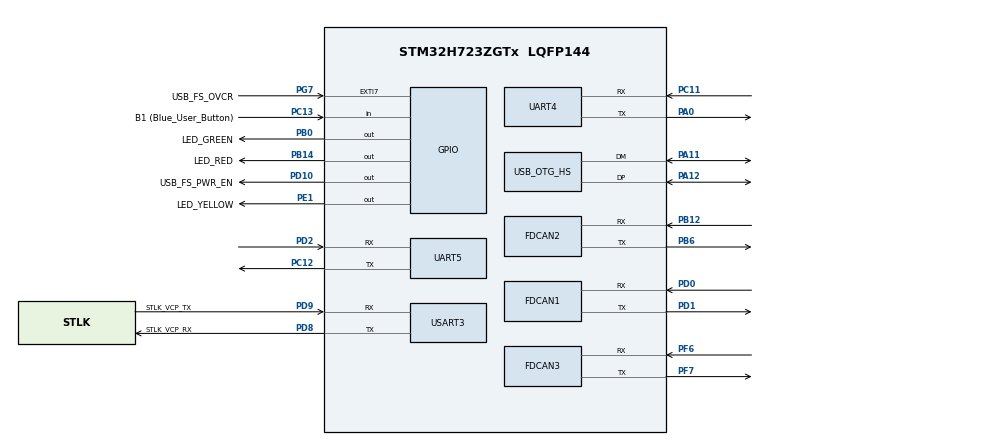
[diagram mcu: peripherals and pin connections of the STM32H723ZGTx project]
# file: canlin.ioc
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Mcu.Family=STM32H7
Mcu.Name=STM32H723ZGTx
Mcu.Package=LQFP144
NVIC.OTG_HS_IRQn=true\:0\:0\:false\:false\:true\:false\:true
NVIC.PriorityGroup=NVIC_PRIORITYGROUP_4
PA0.Mode=LIN
PA0.Signal=UART4_TX
PA1.GPIO_Label=RMII_REF_CLK
PA1.Signal=ETH_REF_CLK
PA10.GPIO_Label=USB_FS_ID
PA10.Signal=USB_OTG_HS_ID
PA11.Mode=Device_Only_FS
PA11.Signal=USB_OTG_HS_DM
PA12.Mode=Device_Only_FS
PA12.Signal=USB_OTG_HS_DP
PA13(JTMS/SWDIO).GPIO_Label=SWDIO
PA13(JTMS/SWDIO).Mode=Trace_Asynchronous_SW
PA13(JTMS/SWDIO).Signal=DEBUG_JTMS-SWDIO
PA14(JTCK/SWCLK).GPIO_Label=SWCLK
PA14(JTCK/SWCLK).Mode=Trace_Asynchronous_SW
PA14(JTCK/SWCLK).Signal=DEBUG_JTCK-SWCLK
PA2.GPIO_Label=RMII_MDIO
PA2.Signal=ETH_MDIO
PA7.GPIO_Label=RMII_CRS_DV
PA7.Signal=ETH_CRS_DV
PA9.GPIO_Label=USB_FS_VBUS
PA9.Signal=USB_OTG_HS_VBUS
PB0.GPIO_Label=LED_GREEN
PB0.Signal=GPIO_Output
PB12.Mode=FDCAN_Activate
PB12.Signal=FDCAN2_RX
PB13.GPIO_Label=RMII_TXD1
PB13.Signal=ETH_TXD1
PB14.GPIO_Label=LED_RED
PB14.Signal=GPIO_Output
PB3(JTDO/TRACESWO).GPIO_Label=SWO
PB3(JTDO/TRACESWO).Mode=Trace_Asynchronous_SW
PB3(JTDO/TRACESWO).Signal=DEBUG_JTDO-SWO
PB6.Mode=FDCAN_Activate
PB6.Signal=FDCAN2_TX
PC1.GPIO_Label=RMII_MDC
PC1.Signal=ETH_MDC
PC11.Mode=LIN
PC11.Signal=UART4_RX
PC12.Mode=LIN
PC12.Signal=UART5_TX
PC13.GPIO_Label=B1 (Blue_User_Button)
PC13.Signal=GPIO_Input
PC14-OSC32_IN.Mode=LSE-External-Oscillator
PC14-OSC32_IN.Signal=RCC_OSC32_IN
PC15-OSC32_OUT.Mode=LSE-External-Oscillator
PC15-OSC32_OUT.Signal=RCC_OSC32_OUT
PC4.GPIO_Label=RMII_RXD0
PC4.Signal=ETH_RXD0
PC5.GPIO_Label=RMII_RXD1
PC5.Signal=ETH_RXD1
PD0.Mode=FDCAN_Activate
PD0.Signal=FDCAN1_RX
PD1.Mode=FDCAN_Activate
PD1.Signal=FDCAN1_TX
PD10.GPIO_Label=USB_FS_PWR_EN
PD10.Signal=GPIO_Output
PD2.Mode=LIN
PD2.Signal=UART5_RX
PD8.GPIO_Label=STLK_VCP_RX
PD8.Mode=Asynchronous
PD8.Signal=USART3_TX
PD9.GPIO_Label=STLK_VCP_TX
PD9.Mode=Asynchronous
PD9.Signal=USART3_RX
PE1.GPIO_Label=LED_YELLOW
PE1.Signal=GPIO_Output
PF6.Mode=FDCAN_Activate
PF6.Signal=FDCAN3_RX
PF7.Mode=FDCAN_Activate
PF7.Signal=FDCAN3_TX
PG11.GPIO_Label=RMII_TX_EN
PG11.Signal=ETH_TX_EN
PG13.GPIO_Label=RMII_TXD0
PG13.Signal=ETH_TXD0
PG7.GPIO_Label=USB_FS_OVCR
PG7.Signal=GPXTI7
PH0-OSC_IN.GPIO_Label=MCO
PH0-OSC_IN.Mode=HSE-External-Clock-Source
PH0-OSC_IN.Signal=RCC_OSC_IN
PH1-OSC_OUT.Signal=RCC_OSC_OUT
ProjectManager.HeapSize=0x1000
ProjectManager.StackSize=0x1000
ProjectManager.TargetToolchain=STM32CubeIDE
RCC.ADCFreq_Value=76000000
RCC.APB1Freq_Value=70000000
RCC.APB2Freq_Value=70000000
RCC.APB3Freq_Value=70000000
RCC.APB4Freq_Value=70000000
RCC.CortexFreq_Value=280000000
RCC.D1PPRE=RCC_APB3_DIV2
RCC.D2PPRE1=RCC_APB1_DIV2
RCC.D2PPRE2=RCC_APB2_DIV2
RCC.D3PPRE=RCC_APB4_DIV2
RCC.DIVM1=4
RCC.DIVM2=1
RCC.DIVN1=140
RCC.DIVN2=19
RCC.DIVP1=1
RCC.DIVQ1=4
RCC.HCLKFreq_Value=140000000
RCC.HPRE=RCC_HCLK_DIV2
RCC.HSE_VALUE=8000000
RCC.PLL1_VCI_Range-AdvancedSettings=RCC_PLL1VCIRANGE_0
RCC.PLL1_VCO_SEL-AdvancedSettings=RCC_PLL1VCOMEDIUM
RCC.PLL2_VCI_Range-AdvancedSettings=RCC_PLL2VCIRANGE_0
RCC.PLL2_VCO_SEL-AdvancedSettings=RCC_PLL2VCOMEDIUM
RCC.PLL3_VCO_SEL-AdvancedSettings=RCC_PLL3VCOMEDIUM
RCC.PLLFRACN=0
RCC.PLLSourceVirtual=RCC_PLLSOURCE_HSE
RCC.SYSCLKFreq_VALUE=280000000
RCC.SYSCLKSource=RCC_SYSCLKSOURCE_PLLCLK
RCC.USBCLockSelection=RCC_USBCLKSOURCE_HSI48
RCC.USBFreq_Value=48000000
UART4.AutoBaudRateEnableParam=UART_ADVFEATURE_AUTOBAUDRATE_ENABLE
UART5.AutoBaudRateEnableParam=UART_ADVFEATURE_AUTOBAUDRATE_ENABLE
USART3.VirtualMode-Asynchronous=VM_ASYNC
USB_DEVICE.APP_RX_DATA_SIZE=512
USB_DEVICE.APP_TX_DATA_SIZE=4
USB_DEVICE.CLASS_NAME_HS=CDC
USB_DEVICE.VirtualMode=Cdc
USB_DEVICE.VirtualModeHS=Cdc_HS
USB_OTG_HS.VirtualMode-Device_Only_FS=Device_Only_FS
VP_USB_DEVICE_VS_USB_DEVICE_CDC_HS.Mode=CDC_HS
board=NUCLEO-H723ZG

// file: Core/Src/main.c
/* USER CODE BEGIN Header */
/**
  ******************************************************************************
  * @file           : main.c
  * @brief          : Main program body
  ******************************************************************************
  * @attention
  *
  * <h2><center>&copy; Copyright (c) 2021 STMicroelectronics.
  * All rights reserved.</center></h2>
  *
  * This software component is licensed by ST under BSD 3-Clause license,
  * the "License"; You may not use this file except in compliance with the
  * License. You may obtain a copy of the License at:
  *                        opensource.org/licenses/BSD-3-Clause
  *
  ******************************************************************************
  */
/* USER CODE END Header */
#include "main.h"
#include "usb_device.h"

/* USER CODE BEGIN Includes */
#include "console.h"

/* USER CODE END Includes */

FDCAN_HandleTypeDef hfdcan1;
FDCAN_HandleTypeDef hfdcan2;
FDCAN_HandleTypeDef hfdcan3;

UART_HandleTypeDef huart4;
UART_HandleTypeDef huart5;
UART_HandleTypeDef huart3;

void SystemClock_Config(void);
static void MX_GPIO_Init(void);
static void MX_USART3_UART_Init(void);
static void MX_FDCAN1_Init(void);
static void MX_FDCAN2_Init(void);
static void MX_FDCAN3_Init(void);
static void MX_UART4_Init(void);
static void MX_UART5_Init(void);

int main(void)
{
  /* USER CODE BEGIN 1 */

  // Turn off buffers, so I/O occurs immediately
  setvbuf(stdin,  NULL, _IONBF, 0);
  setvbuf(stdout, NULL, _IONBF, 0);
  //setvbuf(stderr, NULL, _IONBF, 0);

  /* USER CODE END 1 */

  /* MCU Configuration--------------------------------------------------------*/

  /* Reset of all peripherals, Initializes the Flash interface and the Systick. */
  HAL_Init();

  /* Configure the system clock */
  SystemClock_Config();

  /* Initialize all configured peripherals */
  MX_GPIO_Init();
  MX_USART3_UART_Init();
  MX_FDCAN1_Init();
  MX_FDCAN2_Init();
  MX_FDCAN3_Init();
  MX_UART4_Init();
  MX_UART5_Init();
  MX_USB_DEVICE_Init();

  /* Infinite loop */
  /* USER CODE BEGIN WHILE */
  while (1)
  {
	  if (console_routine())
	  {
		  HAL_GPIO_WritePin(LED_RED_GPIO_Port, LED_RED_Pin, GPIO_PIN_SET);
		  HAL_Delay(1);
		  HAL_GPIO_WritePin(LED_RED_GPIO_Port, LED_RED_Pin, GPIO_PIN_RESET);
	  }
    /* USER CODE END WHILE */

  }
}

void SystemClock_Config(void)
{
  RCC_OscInitTypeDef RCC_OscInitStruct = {0};
  RCC_ClkInitTypeDef RCC_ClkInitStruct = {0};

  /** Supply configuration update enable
  */
  HAL_PWREx_ConfigSupply(PWR_LDO_SUPPLY);
  /** Configure the main internal regulator output voltage
  */
  __HAL_PWR_VOLTAGESCALING_CONFIG(PWR_REGULATOR_VOLTAGE_SCALE2);

  while(!__HAL_PWR_GET_FLAG(PWR_FLAG_VOSRDY)) {}
  /** Initializes the RCC Oscillators according to the specified parameters
  * in the RCC_OscInitTypeDef structure.
  */
  RCC_OscInitStruct.OscillatorType = RCC_OSCILLATORTYPE_HSI48|RCC_OSCILLATORTYPE_HSE;
  RCC_OscInitStruct.HSEState = RCC_HSE_BYPASS;
  RCC_OscInitStruct.HSI48State = RCC_HSI48_ON;
  RCC_OscInitStruct.PLL.PLLState = RCC_PLL_ON;
  RCC_OscInitStruct.PLL.PLLSource = RCC_PLLSOURCE_HSE;
  RCC_OscInitStruct.PLL.PLLM = 4;
  RCC_OscInitStruct.PLL.PLLN = 140;
  RCC_OscInitStruct.PLL.PLLP = 1;
  RCC_OscInitStruct.PLL.PLLQ = 4;
  RCC_OscInitStruct.PLL.PLLR = 2;
  RCC_OscInitStruct.PLL.PLLRGE = RCC_PLL1VCIRANGE_1;
  RCC_OscInitStruct.PLL.PLLVCOSEL = RCC_PLL1VCOWIDE;
  RCC_OscInitStruct.PLL.PLLFRACN = 0;
  if (HAL_RCC_OscConfig(&RCC_OscInitStruct) != HAL_OK)
  {
    Error_Handler();
  }
  /** Initializes the CPU, AHB and APB buses clocks
  */
  RCC_ClkInitStruct.ClockType = RCC_CLOCKTYPE_HCLK|RCC_CLOCKTYPE_SYSCLK
                              |RCC_CLOCKTYPE_PCLK1|RCC_CLOCKTYPE_PCLK2
                              |RCC_CLOCKTYPE_D3PCLK1|RCC_CLOCKTYPE_D1PCLK1;
  RCC_ClkInitStruct.SYSCLKSource = RCC_SYSCLKSOURCE_PLLCLK;
  RCC_ClkInitStruct.SYSCLKDivider = RCC_SYSCLK_DIV1;
  RCC_ClkInitStruct.AHBCLKDivider = RCC_HCLK_DIV2;
  RCC_ClkInitStruct.APB3CLKDivider = RCC_APB3_DIV2;
  RCC_ClkInitStruct.APB1CLKDivider = RCC_APB1_DIV2;
  RCC_ClkInitStruct.APB2CLKDivider = RCC_APB2_DIV2;
  RCC_ClkInitStruct.APB4CLKDivider = RCC_APB4_DIV2;

  if (HAL_RCC_ClockConfig(&RCC_ClkInitStruct, FLASH_LATENCY_2) != HAL_OK)
  {
    Error_Handler();
  }
}

static void MX_FDCAN1_Init(void)
{

  hfdcan1.Instance = FDCAN1;
  hfdcan1.Init.FrameFormat = FDCAN_FRAME_CLASSIC;
  hfdcan1.Init.Mode = FDCAN_MODE_NORMAL;
  hfdcan1.Init.AutoRetransmission = DISABLE;
  hfdcan1.Init.TransmitPause = DISABLE;
  hfdcan1.Init.ProtocolException = DISABLE;
  hfdcan1.Init.NominalPrescaler = 1;
  hfdcan1.Init.NominalSyncJumpWidth = 1;
  hfdcan1.Init.NominalTimeSeg1 = 2;
  hfdcan1.Init.NominalTimeSeg2 = 2;
  hfdcan1.Init.DataPrescaler = 1;
  hfdcan1.Init.DataSyncJumpWidth = 1;
  hfdcan1.Init.DataTimeSeg1 = 1;
  hfdcan1.Init.DataTimeSeg2 = 1;
  hfdcan1.Init.MessageRAMOffset = 0;
  hfdcan1.Init.StdFiltersNbr = 0;
  hfdcan1.Init.ExtFiltersNbr = 0;
  hfdcan1.Init.RxFifo0ElmtsNbr = 0;
  hfdcan1.Init.RxFifo0ElmtSize = FDCAN_DATA_BYTES_8;
  hfdcan1.Init.RxFifo1ElmtsNbr = 0;
  hfdcan1.Init.RxFifo1ElmtSize = FDCAN_DATA_BYTES_8;
  hfdcan1.Init.RxBuffersNbr = 0;
  hfdcan1.Init.RxBufferSize = FDCAN_DATA_BYTES_8;
  hfdcan1.Init.TxEventsNbr = 0;
  hfdcan1.Init.TxBuffersNbr = 0;
  hfdcan1.Init.TxFifoQueueElmtsNbr = 0;
  hfdcan1.Init.TxFifoQueueMode = FDCAN_TX_FIFO_OPERATION;
  hfdcan1.Init.TxElmtSize = FDCAN_DATA_BYTES_8;
  if (HAL_FDCAN_Init(&hfdcan1) != HAL_OK)
  {
    Error_Handler();
  }

}

static void MX_FDCAN2_Init(void)
{

  hfdcan2.Instance = FDCAN2;
  hfdcan2.Init.FrameFormat = FDCAN_FRAME_CLASSIC;
  hfdcan2.Init.Mode = FDCAN_MODE_NORMAL;
  hfdcan2.Init.AutoRetransmission = DISABLE;
  hfdcan2.Init.TransmitPause = DISABLE;
  hfdcan2.Init.ProtocolException = DISABLE;
  hfdcan2.Init.NominalPrescaler = 1;
  hfdcan2.Init.NominalSyncJumpWidth = 1;
  hfdcan2.Init.NominalTimeSeg1 = 2;
  hfdcan2.Init.NominalTimeSeg2 = 2;
  hfdcan2.Init.DataPrescaler = 1;
  hfdcan2.Init.DataSyncJumpWidth = 1;
  hfdcan2.Init.DataTimeSeg1 = 1;
  hfdcan2.Init.DataTimeSeg2 = 1;
  hfdcan2.Init.MessageRAMOffset = 0;
  hfdcan2.Init.StdFiltersNbr = 0;
  hfdcan2.Init.ExtFiltersNbr = 0;
  hfdcan2.Init.RxFifo0ElmtsNbr = 0;
  hfdcan2.Init.RxFifo0ElmtSize = FDCAN_DATA_BYTES_8;
  hfdcan2.Init.RxFifo1ElmtsNbr = 0;
  hfdcan2.Init.RxFifo1ElmtSize = FDCAN_DATA_BYTES_8;
  hfdcan2.Init.RxBuffersNbr = 0;
  hfdcan2.Init.RxBufferSize = FDCAN_DATA_BYTES_8;
  hfdcan2.Init.TxEventsNbr = 0;
  hfdcan2.Init.TxBuffersNbr = 0;
  hfdcan2.Init.TxFifoQueueElmtsNbr = 0;
  hfdcan2.Init.TxFifoQueueMode = FDCAN_TX_FIFO_OPERATION;
  hfdcan2.Init.TxElmtSize = FDCAN_DATA_BYTES_8;
  if (HAL_FDCAN_Init(&hfdcan2) != HAL_OK)
  {
    Error_Handler();
  }

}

static void MX_FDCAN3_Init(void)
{

  hfdcan3.Instance = FDCAN3;
  hfdcan3.Init.FrameFormat = FDCAN_FRAME_CLASSIC;
  hfdcan3.Init.Mode = FDCAN_MODE_NORMAL;
  hfdcan3.Init.AutoRetransmission = DISABLE;
  hfdcan3.Init.TransmitPause = DISABLE;
  hfdcan3.Init.ProtocolException = DISABLE;
  hfdcan3.Init.NominalPrescaler = 1;
  hfdcan3.Init.NominalSyncJumpWidth = 1;
  hfdcan3.Init.NominalTimeSeg1 = 2;
  hfdcan3.Init.NominalTimeSeg2 = 2;
  hfdcan3.Init.DataPrescaler = 1;
  hfdcan3.Init.DataSyncJumpWidth = 1;
  hfdcan3.Init.DataTimeSeg1 = 1;
  hfdcan3.Init.DataTimeSeg2 = 1;
  hfdcan3.Init.MessageRAMOffset = 0;
  hfdcan3.Init.StdFiltersNbr = 0;
  hfdcan3.Init.ExtFiltersNbr = 0;
  hfdcan3.Init.RxFifo0ElmtsNbr = 0;
  hfdcan3.Init.RxFifo0ElmtSize = FDCAN_DATA_BYTES_8;
  hfdcan3.Init.RxFifo1ElmtsNbr = 0;
  hfdcan3.Init.RxFifo1ElmtSize = FDCAN_DATA_BYTES_8;
  hfdcan3.Init.RxBuffersNbr = 0;
  hfdcan3.Init.RxBufferSize = FDCAN_DATA_BYTES_8;
  hfdcan3.Init.TxEventsNbr = 0;
  hfdcan3.Init.TxBuffersNbr = 0;
  hfdcan3.Init.TxFifoQueueElmtsNbr = 0;
  hfdcan3.Init.TxFifoQueueMode = FDCAN_TX_FIFO_OPERATION;
  hfdcan3.Init.TxElmtSize = FDCAN_DATA_BYTES_8;
  if (HAL_FDCAN_Init(&hfdcan3) != HAL_OK)
  {
    Error_Handler();
  }

}

static void MX_UART4_Init(void)
{

  huart4.Instance = UART4;
  huart4.Init.BaudRate = 115200;
  huart4.Init.WordLength = UART_WORDLENGTH_8B;
  huart4.Init.StopBits = UART_STOPBITS_1;
  huart4.Init.Parity = UART_PARITY_NONE;
  huart4.Init.Mode = UART_MODE_TX_RX;
  huart4.Init.HwFlowCtl = UART_HWCONTROL_NONE;
  huart4.Init.OverSampling = UART_OVERSAMPLING_16;
  huart4.Init.OneBitSampling = UART_ONE_BIT_SAMPLE_DISABLE;
  huart4.Init.ClockPrescaler = UART_PRESCALER_DIV1;
  huart4.AdvancedInit.AdvFeatureInit = UART_ADVFEATURE_AUTOBAUDRATE_INIT;
  huart4.AdvancedInit.AutoBaudRateEnable = UART_ADVFEATURE_AUTOBAUDRATE_ENABLE;
  huart4.AdvancedInit.AutoBaudRateMode = UART_ADVFEATURE_AUTOBAUDRATE_ONSTARTBIT;
  if (HAL_LIN_Init(&huart4, UART_LINBREAKDETECTLENGTH_10B) != HAL_OK)
  {
    Error_Handler();
  }
  if (HAL_UARTEx_SetTxFifoThreshold(&huart4, UART_TXFIFO_THRESHOLD_1_8) != HAL_OK)
  {
    Error_Handler();
  }
  if (HAL_UARTEx_SetRxFifoThreshold(&huart4, UART_RXFIFO_THRESHOLD_1_8) != HAL_OK)
  {
    Error_Handler();
  }
  if (HAL_UARTEx_DisableFifoMode(&huart4) != HAL_OK)
  {
    Error_Handler();
  }

}

static void MX_UART5_Init(void)
{

  huart5.Instance = UART5;
  huart5.Init.BaudRate = 115200;
  huart5.Init.WordLength = UART_WORDLENGTH_8B;
  huart5.Init.StopBits = UART_STOPBITS_1;
  huart5.Init.Parity = UART_PARITY_NONE;
  huart5.Init.Mode = UART_MODE_TX_RX;
  huart5.Init.HwFlowCtl = UART_HWCONTROL_NONE;
  huart5.Init.OverSampling = UART_OVERSAMPLING_16;
  huart5.Init.OneBitSampling = UART_ONE_BIT_SAMPLE_DISABLE;
  huart5.Init.ClockPrescaler = UART_PRESCALER_DIV1;
  huart5.AdvancedInit.AdvFeatureInit = UART_ADVFEATURE_AUTOBAUDRATE_INIT;
  huart5.AdvancedInit.AutoBaudRateEnable = UART_ADVFEATURE_AUTOBAUDRATE_ENABLE;
  huart5.AdvancedInit.AutoBaudRateMode = UART_ADVFEATURE_AUTOBAUDRATE_ONSTARTBIT;
  if (HAL_LIN_Init(&huart5, UART_LINBREAKDETECTLENGTH_10B) != HAL_OK)
  {
    Error_Handler();
  }
  if (HAL_UARTEx_SetTxFifoThreshold(&huart5, UART_TXFIFO_THRESHOLD_1_8) != HAL_OK)
  {
    Error_Handler();
  }
  if (HAL_UARTEx_SetRxFifoThreshold(&huart5, UART_RXFIFO_THRESHOLD_1_8) != HAL_OK)
  {
    Error_Handler();
  }
  if (HAL_UARTEx_DisableFifoMode(&huart5) != HAL_OK)
  {
    Error_Handler();
  }

}

static void MX_USART3_UART_Init(void)
{

  huart3.Instance = USART3;
  huart3.Init.BaudRate = 115200;
  huart3.Init.WordLength = UART_WORDLENGTH_8B;
  huart3.Init.StopBits = UART_STOPBITS_1;
  huart3.Init.Parity = UART_PARITY_NONE;
  huart3.Init.Mode = UART_MODE_TX_RX;
  huart3.Init.HwFlowCtl = UART_HWCONTROL_NONE;
  huart3.Init.OverSampling = UART_OVERSAMPLING_16;
  huart3.Init.OneBitSampling = UART_ONE_BIT_SAMPLE_DISABLE;
  huart3.Init.ClockPrescaler = UART_PRESCALER_DIV1;
  huart3.AdvancedInit.AdvFeatureInit = UART_ADVFEATURE_NO_INIT;
  if (HAL_UART_Init(&huart3) != HAL_OK)
  {
    Error_Handler();
  }
  if (HAL_UARTEx_SetTxFifoThreshold(&huart3, UART_TXFIFO_THRESHOLD_1_8) != HAL_OK)
  {
    Error_Handler();
  }
  if (HAL_UARTEx_SetRxFifoThreshold(&huart3, UART_RXFIFO_THRESHOLD_1_8) != HAL_OK)
  {
    Error_Handler();
  }
  if (HAL_UARTEx_DisableFifoMode(&huart3) != HAL_OK)
  {
    Error_Handler();
  }

}

static void MX_GPIO_Init(void)
{
  GPIO_InitTypeDef GPIO_InitStruct = {0};

  /* GPIO Ports Clock Enable */
  __HAL_RCC_GPIOC_CLK_ENABLE();
  __HAL_RCC_GPIOF_CLK_ENABLE();
  __HAL_RCC_GPIOH_CLK_ENABLE();
  __HAL_RCC_GPIOA_CLK_ENABLE();
  __HAL_RCC_GPIOB_CLK_ENABLE();
  __HAL_RCC_GPIOD_CLK_ENABLE();
  __HAL_RCC_GPIOG_CLK_ENABLE();
  __HAL_RCC_GPIOE_CLK_ENABLE();

  /*Configure GPIO pin Output Level */
  HAL_GPIO_WritePin(GPIOB, LED_GREEN_Pin|LED_RED_Pin, GPIO_PIN_RESET);

  /*Configure GPIO pin Output Level */
  HAL_GPIO_WritePin(USB_FS_PWR_EN_GPIO_Port, USB_FS_PWR_EN_Pin, GPIO_PIN_RESET);

  /*Configure GPIO pin Output Level */
  HAL_GPIO_WritePin(LED_YELLOW_GPIO_Port, LED_YELLOW_Pin, GPIO_PIN_RESET);

  /*Configure GPIO pin : B1_Pin */
  GPIO_InitStruct.Pin = B1_Pin;
  GPIO_InitStruct.Mode = GPIO_MODE_INPUT;
  GPIO_InitStruct.Pull = GPIO_NOPULL;
  HAL_GPIO_Init(B1_GPIO_Port, &GPIO_InitStruct);

  /*Configure GPIO pins : RMII_MDC_Pin RMII_RXD0_Pin RMII_RXD1_Pin */
  GPIO_InitStruct.Pin = RMII_MDC_Pin|RMII_RXD0_Pin|RMII_RXD1_Pin;
  GPIO_InitStruct.Mode = GPIO_MODE_AF_PP;
  GPIO_InitStruct.Pull = GPIO_NOPULL;
  GPIO_InitStruct.Speed = GPIO_SPEED_FREQ_LOW;
  GPIO_InitStruct.Alternate = GPIO_AF11_ETH;
  HAL_GPIO_Init(GPIOC, &GPIO_InitStruct);

  /*Configure GPIO pins : RMII_REF_CLK_Pin RMII_MDIO_Pin RMII_CRS_DV_Pin */
  GPIO_InitStruct.Pin = RMII_REF_CLK_Pin|RMII_MDIO_Pin|RMII_CRS_DV_Pin;
  GPIO_InitStruct.Mode = GPIO_MODE_AF_PP;
  GPIO_InitStruct.Pull = GPIO_NOPULL;
  GPIO_InitStruct.Speed = GPIO_SPEED_FREQ_LOW;
  GPIO_InitStruct.Alternate = GPIO_AF11_ETH;
  HAL_GPIO_Init(GPIOA, &GPIO_InitStruct);

  /*Configure GPIO pins : LED_GREEN_Pin LED_RED_Pin */
  GPIO_InitStruct.Pin = LED_GREEN_Pin|LED_RED_Pin;
  GPIO_InitStruct.Mode = GPIO_MODE_OUTPUT_PP;
  GPIO_InitStruct.Pull = GPIO_NOPULL;
  GPIO_InitStruct.Speed = GPIO_SPEED_FREQ_LOW;
  HAL_GPIO_Init(GPIOB, &GPIO_InitStruct);

  /*Configure GPIO pin : RMII_TXD1_Pin */
  GPIO_InitStruct.Pin = RMII_TXD1_Pin;
  GPIO_InitStruct.Mode = GPIO_MODE_AF_PP;
  GPIO_InitStruct.Pull = GPIO_NOPULL;
  GPIO_InitStruct.Speed = GPIO_SPEED_FREQ_LOW;
  GPIO_InitStruct.Alternate = GPIO_AF11_ETH;
  HAL_GPIO_Init(RMII_TXD1_GPIO_Port, &GPIO_InitStruct);

  /*Configure GPIO pin : USB_FS_PWR_EN_Pin */
  GPIO_InitStruct.Pin = USB_FS_PWR_EN_Pin;
  GPIO_InitStruct.Mode = GPIO_MODE_OUTPUT_PP;
  GPIO_InitStruct.Pull = GPIO_NOPULL;
  GPIO_InitStruct.Speed = GPIO_SPEED_FREQ_LOW;
  HAL_GPIO_Init(USB_FS_PWR_EN_GPIO_Port, &GPIO_InitStruct);

  /*Configure GPIO pin : USB_FS_OVCR_Pin */
  GPIO_InitStruct.Pin = USB_FS_OVCR_Pin;
  GPIO_InitStruct.Mode = GPIO_MODE_IT_RISING;
  GPIO_InitStruct.Pull = GPIO_NOPULL;
  HAL_GPIO_Init(USB_FS_OVCR_GPIO_Port, &GPIO_InitStruct);

  /*Configure GPIO pins : RMII_TX_EN_Pin RMII_TXD0_Pin */
  GPIO_InitStruct.Pin = RMII_TX_EN_Pin|RMII_TXD0_Pin;
  GPIO_InitStruct.Mode = GPIO_MODE_AF_PP;
  GPIO_InitStruct.Pull = GPIO_NOPULL;
  GPIO_InitStruct.Speed = GPIO_SPEED_FREQ_LOW;
  GPIO_InitStruct.Alternate = GPIO_AF11_ETH;
  HAL_GPIO_Init(GPIOG, &GPIO_InitStruct);

  /*Configure GPIO pin : LED_YELLOW_Pin */
  GPIO_InitStruct.Pin = LED_YELLOW_Pin;
  GPIO_InitStruct.Mode = GPIO_MODE_OUTPUT_PP;
  GPIO_InitStruct.Pull = GPIO_NOPULL;
  GPIO_InitStruct.Speed = GPIO_SPEED_FREQ_LOW;
  HAL_GPIO_Init(LED_YELLOW_GPIO_Port, &GPIO_InitStruct);

}

void Error_Handler(void)
{
  __disable_irq();
  while (1)
  {
  }
}

/************************ (C) COPYRIGHT STMicroelectronics *****END OF FILE****/
